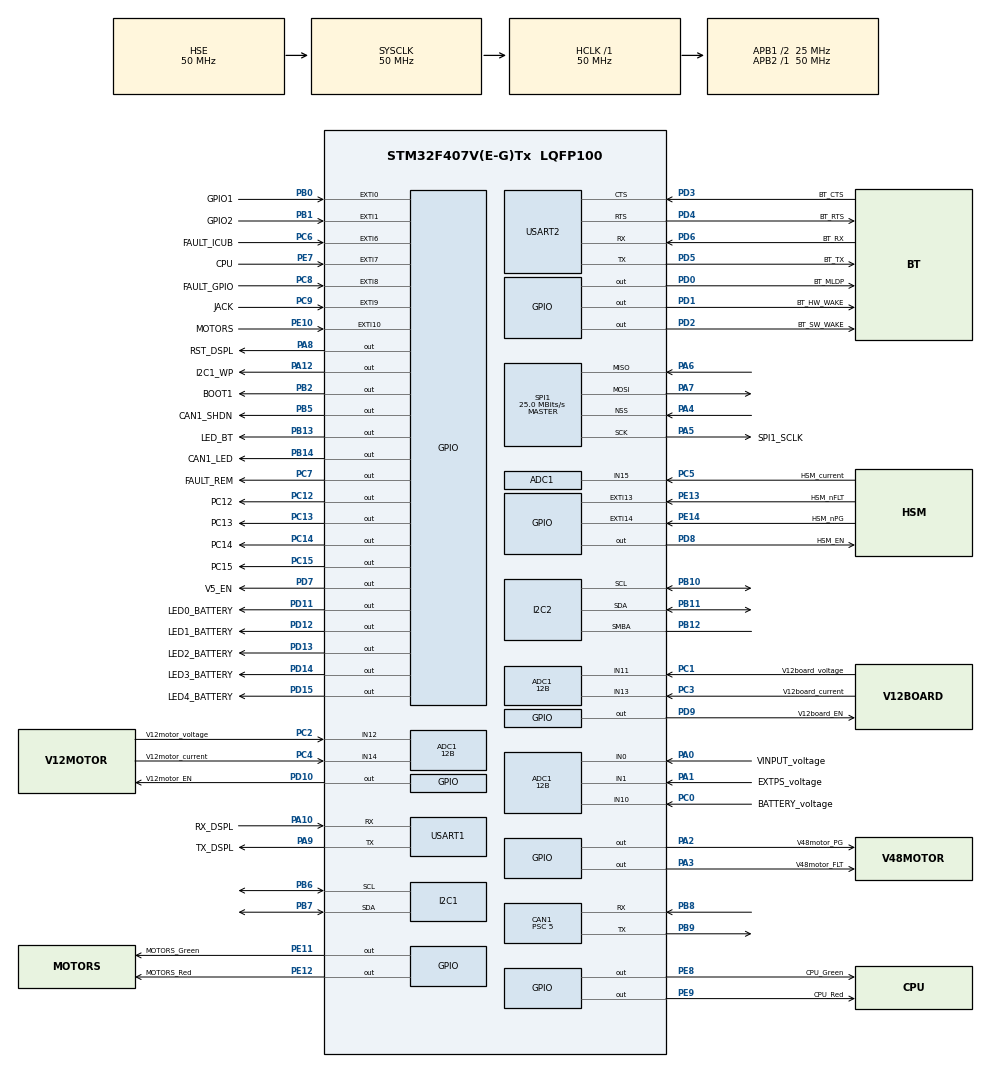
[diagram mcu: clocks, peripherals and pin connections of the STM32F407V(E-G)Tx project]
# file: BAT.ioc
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ADC1.Channel-10\#ChannelRegularConversion=ADC_CHANNEL_10
ADC1.Channel-11\#ChannelRegularConversion=ADC_CHANNEL_11
ADC1.Channel-12\#ChannelRegularConversion=ADC_CHANNEL_12
ADC1.Channel-13\#ChannelRegularConversion=ADC_CHANNEL_13
ADC1.Channel-14\#ChannelRegularConversion=ADC_CHANNEL_14
ADC1.Channel-15\#ChannelRegularConversion=ADC_CHANNEL_15
ADC1.Channel-16\#ChannelRegularConversion=ADC_CHANNEL_TEMPSENSOR
ADC1.Channel-5\#ChannelRegularConversion=ADC_CHANNEL_0
ADC1.Channel-9\#ChannelRegularConversion=ADC_CHANNEL_1
ADC1.ClockPrescaler=ADC_CLOCK_SYNC_PCLK_DIV8
ADC1.ContinuousConvMode=ENABLE
ADC1.DMAContinuousRequests=ENABLE
ADC1.DataAlign=ADC_DATAALIGN_RIGHT
ADC1.DiscontinuousConvMode=DISABLE
ADC1.EOCSelection=ADC_EOC_SEQ_CONV
ADC1.EnableAnalogWatchDog=false
ADC1.ExternalTrigConvEdge=ADC_EXTERNALTRIGCONVEDGE_NONE
ADC1.InjNumberOfConversion=0
ADC1.NbrOfConversion=9
ADC1.NbrOfConversionFlag=1
ADC1.Rank-10\#ChannelRegularConversion=3
ADC1.Rank-11\#ChannelRegularConversion=4
ADC1.Rank-12\#ChannelRegularConversion=5
ADC1.Rank-13\#ChannelRegularConversion=6
ADC1.Rank-14\#ChannelRegularConversion=7
ADC1.Rank-15\#ChannelRegularConversion=8
ADC1.Rank-16\#ChannelRegularConversion=9
ADC1.Rank-5\#ChannelRegularConversion=1
ADC1.Rank-9\#ChannelRegularConversion=2
ADC1.Resolution=ADC_RESOLUTION_12B
ADC1.SamplingTime-10\#ChannelRegularConversion=ADC_SAMPLETIME_15CYCLES
ADC1.SamplingTime-11\#ChannelRegularConversion=ADC_SAMPLETIME_15CYCLES
ADC1.SamplingTime-12\#ChannelRegularConversion=ADC_SAMPLETIME_15CYCLES
ADC1.SamplingTime-13\#ChannelRegularConversion=ADC_SAMPLETIME_15CYCLES
ADC1.SamplingTime-14\#ChannelRegularConversion=ADC_SAMPLETIME_15CYCLES
ADC1.SamplingTime-15\#ChannelRegularConversion=ADC_SAMPLETIME_15CYCLES
ADC1.SamplingTime-16\#ChannelRegularConversion=ADC_SAMPLETIME_15CYCLES
ADC1.SamplingTime-5\#ChannelRegularConversion=ADC_SAMPLETIME_15CYCLES
ADC1.SamplingTime-9\#ChannelRegularConversion=ADC_SAMPLETIME_15CYCLES
ADC1.ScanConvMode=ENABLE
ADC1.master=1
CAN1.ABOM=ENABLE
CAN1.AWUM=ENABLE
CAN1.BS1=CAN_BS1_2TQ
CAN1.BS2=CAN_BS2_2TQ
CAN1.CalculateTimeBit=600
CAN1.CalculateTimeQuantum=200.0
CAN1.Mode=CAN_MODE_LOOPBACK
CAN1.Prescaler=5
CAN1.TXFP=DISABLE
Dma.ADC1.3.Direction=DMA_PERIPH_TO_MEMORY
Dma.ADC1.3.FIFOMode=DMA_FIFOMODE_DISABLE
Dma.ADC1.3.Instance=DMA2_Stream0
Dma.ADC1.3.MemDataAlignment=DMA_MDATAALIGN_WORD
Dma.ADC1.3.MemInc=DMA_MINC_ENABLE
Dma.ADC1.3.Mode=DMA_CIRCULAR
Dma.ADC1.3.PeriphDataAlignment=DMA_PDATAALIGN_WORD
Dma.ADC1.3.PeriphInc=DMA_PINC_DISABLE
Dma.ADC1.3.Priority=DMA_PRIORITY_LOW
Dma.Request0=USART2_RX
Dma.Request1=USART2_TX
Dma.Request2=USART1_TX
Dma.Request3=ADC1
Dma.USART1_TX.2.Direction=DMA_MEMORY_TO_PERIPH
Dma.USART1_TX.2.FIFOMode=DMA_FIFOMODE_DISABLE
Dma.USART1_TX.2.Instance=DMA2_Stream7
Dma.USART1_TX.2.MemDataAlignment=DMA_MDATAALIGN_BYTE
Dma.USART1_TX.2.MemInc=DMA_MINC_ENABLE
Dma.USART1_TX.2.Mode=DMA_NORMAL
Dma.USART1_TX.2.PeriphDataAlignment=DMA_PDATAALIGN_BYTE
Dma.USART1_TX.2.PeriphInc=DMA_PINC_DISABLE
Dma.USART1_TX.2.Priority=DMA_PRIORITY_LOW
Dma.USART2_RX.0.Direction=DMA_PERIPH_TO_MEMORY
Dma.USART2_RX.0.FIFOMode=DMA_FIFOMODE_DISABLE
Dma.USART2_RX.0.Instance=DMA1_Stream5
Dma.USART2_RX.0.MemDataAlignment=DMA_MDATAALIGN_BYTE
Dma.USART2_RX.0.MemInc=DMA_MINC_ENABLE
Dma.USART2_RX.0.Mode=DMA_NORMAL
Dma.USART2_RX.0.PeriphDataAlignment=DMA_PDATAALIGN_BYTE
Dma.USART2_RX.0.PeriphInc=DMA_PINC_DISABLE
Dma.USART2_RX.0.Priority=DMA_PRIORITY_LOW
Dma.USART2_TX.1.Direction=DMA_MEMORY_TO_PERIPH
Dma.USART2_TX.1.FIFOMode=DMA_FIFOMODE_DISABLE
Dma.USART2_TX.1.Instance=DMA1_Stream6
Dma.USART2_TX.1.MemDataAlignment=DMA_MDATAALIGN_BYTE
Dma.USART2_TX.1.MemInc=DMA_MINC_ENABLE
Dma.USART2_TX.1.Mode=DMA_NORMAL
Dma.USART2_TX.1.PeriphDataAlignment=DMA_PDATAALIGN_BYTE
Dma.USART2_TX.1.PeriphInc=DMA_PINC_DISABLE
Dma.USART2_TX.1.Priority=DMA_PRIORITY_LOW
Mcu.Family=STM32F4
Mcu.Name=STM32F407V(E-G)Tx
Mcu.Package=LQFP100
NVIC.CAN1_RX0_IRQn=true\:0\:0\:false\:false\:true\:true
NVIC.CAN1_RX1_IRQn=true\:0\:0\:false\:false\:true\:true
NVIC.CAN1_SCE_IRQn=true\:0\:0\:false\:false\:true\:true
NVIC.CAN1_TX_IRQn=true\:0\:0\:false\:false\:true\:true
NVIC.DMA1_Stream5_IRQn=true\:0\:0\:false\:false\:true\:true
NVIC.DMA1_Stream6_IRQn=true\:0\:0\:false\:false\:true\:true
NVIC.DMA2_Stream0_IRQn=true\:0\:0\:false\:false\:true\:true
NVIC.DMA2_Stream7_IRQn=true\:0\:0\:false\:false\:true\:true
NVIC.EXTI0_IRQn=true\:0\:0\:false\:false\:true\:true
NVIC.EXTI15_10_IRQn=true\:0\:0\:false\:false\:true\:true
NVIC.EXTI1_IRQn=true\:0\:0\:false\:false\:true\:true
NVIC.EXTI9_5_IRQn=true\:0\:0\:false\:false\:true\:true
NVIC.PriorityGroup=NVIC_PRIORITYGROUP_4
NVIC.TIM1_TRG_COM_TIM11_IRQn=true\:0\:0\:false\:false\:true\:true
NVIC.TIM1_UP_TIM10_IRQn=true\:0\:0\:false\:false\:true\:true
NVIC.TIM2_IRQn=true\:0\:0\:false\:false\:true\:true
NVIC.TIM6_DAC_IRQn=true\:0\:0\:false\:false\:true\:true
NVIC.TIM7_IRQn=true\:0\:0\:false\:false\:true\:true
NVIC.TIM8_UP_TIM13_IRQn=true\:0\:0\:false\:false\:true\:true
NVIC.USART1_IRQn=true\:0\:0\:true\:false\:true\:true
NVIC.USART2_IRQn=true\:0\:0\:false\:false\:true\:true
PA0-WKUP.GPIO_Label=VINPUT_voltage
PA0-WKUP.GPIO_Mode=GPIO_MODE_ANALOG
PA0-WKUP.GPIO_PuPd=GPIO_NOPULL
PA0-WKUP.Signal=ADCx_IN0
PA1.GPIO_Label=EXTPS_voltage
PA1.GPIO_Mode=GPIO_MODE_ANALOG
PA1.GPIO_PuPd=GPIO_NOPULL
PA1.Signal=ADCx_IN1
PA10.GPIO_Label=RX_DSPL
PA10.GPIO_Mode=GPIO_MODE_AF_PP
PA10.GPIO_PuPd=GPIO_PULLUP
PA10.GPIO_Speed=GPIO_SPEED_FREQ_VERY_HIGH
PA10.Mode=Asynchronous
PA10.Signal=USART1_RX
PA12.GPIO_Label=I2C1_WP
PA12.GPIO_ModeDefaultOutputPP=GPIO_MODE_OUTPUT_PP
PA12.GPIO_PuPd=GPIO_NOPULL
PA12.GPIO_Speed=GPIO_SPEED_FREQ_LOW
PA12.Signal=GPIO_Output
PA13.Mode=Trace-Synchro(4bits)_JTAG
PA13.Signal=SYS_JTMS-SWDIO
PA14.Mode=Trace-Synchro(4bits)_JTAG
PA14.Signal=SYS_JTCK-SWCLK
PA15.Mode=Trace-Synchro(4bits)_JTAG
PA15.Signal=SYS_JTDI
PA2.GPIO_Label=V48motor_PG
PA2.GPIO_ModeDefaultOutputPP=GPIO_MODE_OUTPUT_PP
PA2.GPIO_PuPd=GPIO_NOPULL
PA2.GPIO_Speed=GPIO_SPEED_FREQ_LOW
PA2.Signal=GPIO_Output
PA3.GPIO_Label=V48motor_FLT
PA3.GPIO_ModeDefaultOutputPP=GPIO_MODE_OUTPUT_PP
PA3.GPIO_PuPd=GPIO_NOPULL
PA3.GPIO_Speed=GPIO_SPEED_FREQ_LOW
PA3.Signal=GPIO_Output
PA4.Mode=NSS_Signal_Hard_Input
PA4.Signal=SPI1_NSS
PA5.GPIO_Label=SPI1_SCLK
PA5.GPIO_Mode=GPIO_MODE_AF_PP
PA5.GPIO_PuPd=GPIO_NOPULL
PA5.GPIO_Speed=GPIO_SPEED_FREQ_VERY_HIGH
PA5.Mode=Full_Duplex_Master
PA5.Signal=SPI1_SCK
PA6.Mode=Full_Duplex_Master
PA6.Signal=SPI1_MISO
PA7.Mode=Full_Duplex_Master
PA7.Signal=SPI1_MOSI
PA8.GPIO_Label=RST_DSPL
PA8.GPIO_ModeDefaultOutputPP=GPIO_MODE_OUTPUT_PP
PA8.GPIO_PuPd=GPIO_NOPULL
PA8.GPIO_Speed=GPIO_SPEED_FREQ_LOW
PA8.Signal=GPIO_Output
PA9.GPIO_Label=TX_DSPL
PA9.GPIO_Mode=GPIO_MODE_AF_PP
PA9.GPIO_PuPd=GPIO_PULLUP
PA9.GPIO_Speed=GPIO_SPEED_FREQ_VERY_HIGH
PA9.Mode=Asynchronous
PA9.Signal=USART1_TX
PB0.GPIO_Label=GPIO1
PB0.GPIO_ModeDefaultEXTI=GPIO_MODE_IT_FALLING
PB0.GPIO_PuPd=GPIO_PULLUP
PB0.Signal=GPXTI0
PB1.GPIO_Label=GPIO2
PB1.GPIO_ModeDefaultEXTI=GPIO_MODE_IT_FALLING
PB1.GPIO_PuPd=GPIO_PULLUP
PB1.Signal=GPXTI1
PB10.Mode=SMBus-Alert-mode
PB10.Signal=I2C2_SCL
PB11.Mode=SMBus-Alert-mode
PB11.Signal=I2C2_SDA
PB12.Mode=SMBus-Alert-mode
PB12.Signal=I2C2_SMBA
PB13.GPIO_Label=LED_BT
PB13.GPIO_ModeDefaultOutputPP=GPIO_MODE_OUTPUT_PP
PB13.GPIO_PuPd=GPIO_NOPULL
PB13.GPIO_Speed=GPIO_SPEED_FREQ_LOW
PB13.Signal=GPIO_Output
PB14.GPIO_Label=CAN1_LED
PB14.GPIO_ModeDefaultOutputPP=GPIO_MODE_OUTPUT_PP
PB14.GPIO_PuPd=GPIO_NOPULL
PB14.GPIO_Speed=GPIO_SPEED_FREQ_LOW
PB14.Signal=GPIO_Output
PB2.GPIO_Label=BOOT1
PB2.GPIO_ModeDefaultOutputPP=GPIO_MODE_OUTPUT_PP
PB2.GPIO_PuPd=GPIO_NOPULL
PB2.GPIO_Speed=GPIO_SPEED_FREQ_LOW
PB2.Signal=GPIO_Output
PB3.Mode=Trace-Synchro(4bits)_JTAG
PB3.Signal=SYS_JTDO-SWO
PB5.GPIO_Label=CAN1_SHDN
PB5.GPIO_ModeDefaultOutputPP=GPIO_MODE_OUTPUT_PP
PB5.GPIO_PuPd=GPIO_NOPULL
PB5.GPIO_Speed=GPIO_SPEED_FREQ_LOW
PB5.Signal=GPIO_Output
PB6.Mode=I2C
PB6.Signal=I2C1_SCL
PB7.Mode=I2C
PB7.Signal=I2C1_SDA
PB8.Mode=Master
PB8.Signal=CAN1_RX
PB9.Mode=Master
PB9.Signal=CAN1_TX
PC0.GPIO_Label=BATTERY_voltage
PC0.GPIO_Mode=GPIO_MODE_ANALOG
PC0.GPIO_PuPd=GPIO_NOPULL
PC0.Signal=ADCx_IN10
PC1.GPIO_Label=V12board_voltage
PC1.GPIO_Mode=GPIO_MODE_ANALOG
PC1.GPIO_PuPd=GPIO_NOPULL
PC1.Signal=ADCx_IN11
PC12.GPIO_Label=PC12
PC12.GPIO_ModeDefaultOutputPP=GPIO_MODE_OUTPUT_PP
PC12.GPIO_PuPd=GPIO_NOPULL
PC12.GPIO_Speed=GPIO_SPEED_FREQ_LOW
PC12.Signal=GPIO_Output
PC13-ANTI_TAMP.GPIO_Label=PC13
PC13-ANTI_TAMP.GPIO_ModeDefaultOutputPP=GPIO_MODE_OUTPUT_PP
PC13-ANTI_TAMP.GPIO_PuPd=GPIO_NOPULL
PC13-ANTI_TAMP.GPIO_Speed=GPIO_SPEED_FREQ_LOW
PC13-ANTI_TAMP.Signal=GPIO_Output
PC14-OSC32_IN.GPIO_Label=PC14
PC14-OSC32_IN.GPIO_ModeDefaultOutputPP=GPIO_MODE_OUTPUT_PP
PC14-OSC32_IN.GPIO_PuPd=GPIO_NOPULL
PC14-OSC32_IN.GPIO_Speed=GPIO_SPEED_FREQ_LOW
PC14-OSC32_IN.Signal=GPIO_Output
PC15-OSC32_OUT.GPIO_Label=PC15
PC15-OSC32_OUT.GPIO_ModeDefaultOutputPP=GPIO_MODE_OUTPUT_PP
PC15-OSC32_OUT.GPIO_PuPd=GPIO_NOPULL
PC15-OSC32_OUT.GPIO_Speed=GPIO_SPEED_FREQ_LOW
PC15-OSC32_OUT.Signal=GPIO_Output
PC2.GPIO_Label=V12motor_voltage
PC2.GPIO_Mode=GPIO_MODE_ANALOG
PC2.GPIO_PuPd=GPIO_NOPULL
PC2.Signal=ADCx_IN12
PC3.GPIO_Label=V12board_current
PC3.GPIO_Mode=GPIO_MODE_ANALOG
PC3.GPIO_PuPd=GPIO_NOPULL
PC3.Signal=ADCx_IN13
PC4.GPIO_Label=V12motor_current
PC4.GPIO_Mode=GPIO_MODE_ANALOG
PC4.GPIO_PuPd=GPIO_NOPULL
PC4.Signal=ADCx_IN14
PC5.GPIO_Label=HSM_current
PC5.GPIO_Mode=GPIO_MODE_ANALOG
PC5.GPIO_PuPd=GPIO_NOPULL
PC5.Signal=ADCx_IN15
PC6.GPIO_Label=FAULT_ICUB
PC6.GPIO_ModeDefaultEXTI=GPIO_MODE_IT_FALLING
PC6.GPIO_PuPd=GPIO_PULLUP
PC6.Signal=GPXTI6
PC7.GPIO_Label=FAULT_REM
PC7.GPIO_ModeDefaultOutputPP=GPIO_MODE_OUTPUT_PP
PC7.GPIO_PuPd=GPIO_PULLDOWN
PC7.GPIO_Speed=GPIO_SPEED_FREQ_LOW
PC7.Signal=GPIO_Output
PC8.GPIO_Label=FAULT_GPIO
PC8.GPIO_ModeDefaultEXTI=GPIO_MODE_IT_FALLING
PC8.GPIO_PuPd=GPIO_PULLUP
PC8.Signal=GPXTI8
PC9.GPIO_Label=JACK
PC9.GPIO_ModeDefaultEXTI=GPIO_MODE_IT_FALLING
PC9.GPIO_PuPd=GPIO_PULLUP
PC9.Signal=GPXTI9
PD0.GPIO_Label=BT_MLDP
PD0.GPIO_ModeDefaultOutputPP=GPIO_MODE_OUTPUT_PP
PD0.GPIO_PuPd=GPIO_NOPULL
PD0.GPIO_Speed=GPIO_SPEED_FREQ_LOW
PD0.Signal=GPIO_Output
PD1.GPIO_Label=BT_HW_WAKE
PD1.GPIO_ModeDefaultOutputPP=GPIO_MODE_OUTPUT_PP
PD1.GPIO_PuPd=GPIO_NOPULL
PD1.GPIO_Speed=GPIO_SPEED_FREQ_LOW
PD1.Signal=GPIO_Output
PD10.GPIO_Label=V12motor_EN
PD10.GPIO_ModeDefaultOutputPP=GPIO_MODE_OUTPUT_PP
PD10.GPIO_PuPd=GPIO_NOPULL
PD10.GPIO_Speed=GPIO_SPEED_FREQ_LOW
PD10.Signal=GPIO_Output
PD11.GPIO_Label=LED0_BATTERY
PD11.GPIO_ModeDefaultOutputPP=GPIO_MODE_OUTPUT_PP
PD11.GPIO_PuPd=GPIO_NOPULL
PD11.GPIO_Speed=GPIO_SPEED_FREQ_LOW
PD11.Signal=GPIO_Output
PD12.GPIO_Label=LED1_BATTERY
PD12.GPIO_ModeDefaultOutputPP=GPIO_MODE_OUTPUT_PP
PD12.GPIO_PuPd=GPIO_NOPULL
PD12.GPIO_Speed=GPIO_SPEED_FREQ_LOW
PD12.Signal=GPIO_Output
PD13.GPIO_Label=LED2_BATTERY
PD13.GPIO_ModeDefaultOutputPP=GPIO_MODE_OUTPUT_PP
PD13.GPIO_PuPd=GPIO_NOPULL
PD13.GPIO_Speed=GPIO_SPEED_FREQ_LOW
PD13.Signal=GPIO_Output
PD14.GPIO_Label=LED3_BATTERY
PD14.GPIO_ModeDefaultOutputPP=GPIO_MODE_OUTPUT_PP
PD14.GPIO_PuPd=GPIO_NOPULL
PD14.GPIO_Speed=GPIO_SPEED_FREQ_LOW
PD14.Signal=GPIO_Output
PD15.GPIO_Label=LED4_BATTERY
PD15.GPIO_ModeDefaultOutputPP=GPIO_MODE_OUTPUT_PP
PD15.GPIO_PuPd=GPIO_NOPULL
PD15.GPIO_Speed=GPIO_SPEED_FREQ_LOW
PD15.Signal=GPIO_Output
PD2.GPIO_Label=BT_SW_WAKE
PD2.GPIO_ModeDefaultOutputPP=GPIO_MODE_OUTPUT_PP
PD2.GPIO_PuPd=GPIO_NOPULL
PD2.GPIO_Speed=GPIO_SPEED_FREQ_LOW
PD2.Signal=GPIO_Output
PD3.GPIO_Label=BT_CTS
PD3.GPIO_Mode=GPIO_MODE_AF_PP
PD3.GPIO_PuPd=GPIO_NOPULL
PD3.GPIO_Speed=GPIO_SPEED_FREQ_VERY_HIGH
PD3.Mode=CTS_RTS
PD3.Signal=USART2_CTS
PD4.GPIO_Label=BT_RTS
PD4.GPIO_Mode=GPIO_MODE_AF_PP
PD4.GPIO_PuPd=GPIO_NOPULL
PD4.GPIO_Speed=GPIO_SPEED_FREQ_VERY_HIGH
PD4.Mode=CTS_RTS
PD4.Signal=USART2_RTS
PD5.GPIO_Label=BT_TX
PD5.GPIO_Mode=GPIO_MODE_AF_PP
PD5.GPIO_PuPd=GPIO_PULLUP
PD5.GPIO_Speed=GPIO_SPEED_FREQ_VERY_HIGH
PD5.Mode=Asynchronous
PD5.Signal=USART2_TX
PD6.GPIO_Label=BT_RX
PD6.GPIO_Mode=GPIO_MODE_AF_PP
PD6.GPIO_PuPd=GPIO_PULLUP
PD6.GPIO_Speed=GPIO_SPEED_FREQ_VERY_HIGH
PD6.Mode=Asynchronous
PD6.Signal=USART2_RX
PD7.GPIO_Label=V5_EN
PD7.GPIO_ModeDefaultOutputPP=GPIO_MODE_OUTPUT_PP
PD7.GPIO_PuPd=GPIO_NOPULL
PD7.GPIO_Speed=GPIO_SPEED_FREQ_LOW
PD7.Signal=GPIO_Output
PD8.GPIO_Label=HSM_EN
PD8.GPIO_ModeDefaultOutputPP=GPIO_MODE_OUTPUT_PP
PD8.GPIO_PuPd=GPIO_NOPULL
PD8.GPIO_Speed=GPIO_SPEED_FREQ_LOW
PD8.Signal=GPIO_Output
PD9.GPIO_Label=V12board_EN
PD9.GPIO_ModeDefaultOutputPP=GPIO_MODE_OUTPUT_PP
PD9.GPIO_PuPd=GPIO_NOPULL
PD9.GPIO_Speed=GPIO_SPEED_FREQ_LOW
PD9.Signal=GPIO_Output
PE10.GPIO_Label=MOTORS
PE10.GPIO_ModeDefaultEXTI=GPIO_MODE_IT_FALLING
PE10.GPIO_PuPd=GPIO_PULLUP
PE10.Signal=GPXTI10
PE11.GPIO_Label=MOTORS_Green
PE11.GPIO_ModeDefaultOutputPP=GPIO_MODE_OUTPUT_PP
PE11.GPIO_PuPd=GPIO_NOPULL
PE11.GPIO_Speed=GPIO_SPEED_FREQ_LOW
PE11.Signal=GPIO_Output
PE12.GPIO_Label=MOTORS_Red
PE12.GPIO_ModeDefaultOutputPP=GPIO_MODE_OUTPUT_PP
PE12.GPIO_PuPd=GPIO_NOPULL
PE12.GPIO_Speed=GPIO_SPEED_FREQ_LOW
PE12.Signal=GPIO_Output
PE13.GPIO_Label=HSM_nFLT
PE13.GPIO_ModeDefaultEXTI=GPIO_MODE_IT_RISING_FALLING
PE13.GPIO_PuPd=GPIO_PULLUP
PE13.Signal=GPXTI13
PE14.GPIO_Label=HSM_nPG
PE14.GPIO_ModeDefaultEXTI=GPIO_MODE_IT_RISING_FALLING
PE14.GPIO_PuPd=GPIO_PULLUP
PE14.Signal=GPXTI14
PE2.Mode=Trace-Synchro(4bits)_JTAG
PE2.Signal=SYS_TRACECLK
PE3.Mode=Trace-Synchro(4bits)_JTAG
PE3.Signal=SYS_TRACED0
PE4.Mode=Trace-Synchro(4bits)_JTAG
PE4.Signal=SYS_TRACED1
PE5.Mode=Trace-Synchro(4bits)_JTAG
PE5.Signal=SYS_TRACED2
PE6.Mode=Trace-Synchro(4bits)_JTAG
PE6.Signal=SYS_TRACED3
PE7.GPIO_Label=CPU
PE7.GPIO_ModeDefaultEXTI=GPIO_MODE_IT_FALLING
PE7.GPIO_PuPd=GPIO_PULLUP
PE7.Signal=GPXTI7
PE8.GPIO_Label=CPU_Green
PE8.GPIO_ModeDefaultOutputPP=GPIO_MODE_OUTPUT_PP
PE8.GPIO_PuPd=GPIO_NOPULL
PE8.GPIO_Speed=GPIO_SPEED_FREQ_LOW
PE8.Signal=GPIO_Output
PE9.GPIO_Label=CPU_Red
PE9.GPIO_ModeDefaultOutputPP=GPIO_MODE_OUTPUT_PP
PE9.GPIO_PuPd=GPIO_NOPULL
PE9.GPIO_Speed=GPIO_SPEED_FREQ_LOW
PE9.Signal=GPIO_Output
PH0-OSC_IN.Mode=HSE-External-Clock-Source
PH0-OSC_IN.Signal=RCC_OSC_IN
PH1-OSC_OUT.Mode=HSE-External-Clock-Source
PH1-OSC_OUT.Signal=RCC_OSC_OUT
ProjectManager.HeapSize=0x200
ProjectManager.StackSize=0x400
ProjectManager.TargetToolchain=MDK-ARM V5
RCC.48MHZClocksFreq_Value=150000000
RCC.AHBFreq_Value=50000000
RCC.APB1CLKDivider=RCC_HCLK_DIV2
RCC.APB1Freq_Value=25000000
RCC.APB1TimFreq_Value=50000000
RCC.APB2Freq_Value=50000000
RCC.APB2TimFreq_Value=50000000
RCC.CortexFreq_Value=50000000
RCC.HCLKFreq_Value=50000000
RCC.HSE_VALUE=50000000
RCC.HSI_VALUE=16000000
RCC.LSE_VALUE=32768
RCC.PLLSourceVirtual=RCC_PLLSOURCE_HSE
RCC.SYSCLKFreq_VALUE=50000000
RCC.SYSCLKSource=RCC_SYSCLKSOURCE_HSE
RCC.VCOOutputFreq_Value=600000000
SH.ADCx_IN0.0=ADC1_IN0,IN0
SH.ADCx_IN1.0=ADC1_IN1,IN1
SH.ADCx_IN10.0=ADC1_IN10,IN10
SH.ADCx_IN11.0=ADC1_IN11,IN11
SH.ADCx_IN12.0=ADC1_IN12,IN12
SH.ADCx_IN13.0=ADC1_IN13,IN13
SH.ADCx_IN14.0=ADC1_IN14,IN14
SH.ADCx_IN15.0=ADC1_IN15,IN15
SPI1.CalculateBaudRate=25.0 MBits/s
SPI1.Direction=SPI_DIRECTION_2LINES
SPI1.Mode=SPI_MODE_MASTER
SPI1.VirtualNSS=VM_NSSHARD
SPI1.VirtualType=VM_MASTER
TIM1.Period=5000
TIM1.Prescaler=100
TIM10.Period=5000
TIM10.Prescaler=100
TIM11.Period=5000
TIM11.Prescaler=1000
TIM13.Period=5000
TIM13.Prescaler=10000
TIM2.Period=5000
TIM2.Prescaler=100
TIM6.Period=5000
TIM6.Prescaler=0
TIM6.TIM_MasterOutputTrigger=TIM_TRGO_RESET
TIM7.Period=5000
TIM7.Prescaler=10
USART1.VirtualMode=VM_ASYNC
USART2.VirtualMode=VM_ASYNC
VP_ADC1_TempSens_Input.Mode=IN-TempSens
VP_TIM10_VS_ClockSourceINT.Mode=Enable_Timer
VP_TIM11_VS_ClockSourceINT.Mode=Enable_Timer
VP_TIM13_VS_ClockSourceINT.Mode=Enable_Timer
VP_TIM1_VS_ClockSourceINT.Mode=Internal
VP_TIM2_VS_ClockSourceINT.Mode=Internal
VP_TIM6_VS_ClockSourceINT.Mode=Enable_Timer
VP_TIM7_VS_ClockSourceINT.Mode=Enable_Timer
board=BAT

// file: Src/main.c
/**
  ******************************************************************************
  * File Name          : main.c
  * Description        : Main program body
  ******************************************************************************
  *
  * COPYRIGHT(c) 2018 STMicroelectronics
  *
  * Redistribution and use in source and binary forms, with or without modification,
  * are permitted provided that the following conditions are met:
  *   1. Redistributions of source code must retain the above copyright notice,
  *      this list of conditions and the following disclaimer.
  *   2. Redistributions in binary form must reproduce the above copyright notice,
  *      this list of conditions and the following disclaimer in the documentation
  *      and/or other materials provided with the distribution.
  *   3. Neither the name of STMicroelectronics nor the names of its contributors
  *      may be used to endorse or promote products derived from this software
  *      without specific prior written permission.
  *
  * THIS SOFTWARE IS PROVIDED BY THE COPYRIGHT HOLDERS AND CONTRIBUTORS "AS IS"
  * AND ANY EXPRESS OR IMPLIED WARRANTIES, INCLUDING, BUT NOT LIMITED TO, THE
  * IMPLIED WARRANTIES OF MERCHANTABILITY AND FITNESS FOR A PARTICULAR PURPOSE ARE
  * DISCLAIMED. IN NO EVENT SHALL THE COPYRIGHT HOLDER OR CONTRIBUTORS BE LIABLE
  * FOR ANY DIRECT, INDIRECT, INCIDENTAL, SPECIAL, EXEMPLARY, OR CONSEQUENTIAL
  * DAMAGES (INCLUDING, BUT NOT LIMITED TO, PROCUREMENT OF SUBSTITUTE GOODS OR
  * SERVICES; LOSS OF USE, DATA, OR PROFITS; OR BUSINESS INTERRUPTION) HOWEVER
  * CAUSED AND ON ANY THEORY OF LIABILITY, WHETHER IN CONTRACT, STRICT LIABILITY,
  * OR TORT (INCLUDING NEGLIGENCE OR OTHERWISE) ARISING IN ANY WAY OUT OF THE USE
  * OF THIS SOFTWARE, EVEN IF ADVISED OF THE POSSIBILITY OF SUCH DAMAGE.
  *
  ******************************************************************************
  */
#include "stm32f4xx_hal.h"
#include "adc.h"
#include "can.h"
#include "dma.h"
#include "i2c.h"
#include "spi.h"
#include "tim.h"
#include "usart.h"
#include "gpio.h"

/* USER CODE BEGIN Includes */
#include "define.h"

/* USER CODE END Includes */

/* USER CODE BEGIN PV */

// ----------------------------------------------------------------------------
// Firmware Version
// ----------------------------------------------------------------------------
char Firmware_vers = 1;
char Revision_vers = 1;
char Build_number  = 0;

/* Private variables ---------------------------------------------------------*/
typedef struct
{
  uint32_t V_VINPUT;
  uint32_t V_EXTPS;
  uint32_t V_BATTERY;
  uint32_t V_V12board;
  uint32_t V_V12motor;
  int32_t I_V12board;
  int32_t I_V12motor;
  int32_t I_HSM;
  int32_t Temp_sensor;
}adc_measure_t;

adc_measure_t adc_measure = {0};  // initialize all adc values to 0
adc_measure_t mean = {0};         // initialize all average values to 0
uint32_t adc_values[9];           // contains all ADC channels conversion

#define nr_adc_sample (uint16_t) 400 // number of samples for the average measure
uint16_t adc_sample = 0;

typedef struct
{
  uint32_t V_VINPUT[nr_adc_sample];
  uint32_t V_EXTPS[nr_adc_sample];
  uint32_t V_BATTERY[nr_adc_sample];
  uint32_t V_V12board[nr_adc_sample];
  uint32_t V_V12motor[nr_adc_sample];
  int32_t I_V12board[nr_adc_sample];
  int32_t I_V12motor[nr_adc_sample];
  int32_t I_HSM[nr_adc_sample];
}fifo;

fifo adc_samples = {0};

#ifdef BAT_R1
uint32_t VTH[7]={23000, 24000, 25000, 26000, 27000, 28000, 29000};   // threshold in mV R1 Battery
uint16_t Battery_high=4200*7;   // 7s5p battery
uint16_t Battery_low=3300*7;    // 7s5p battery
#endif

#ifdef BAT_iCub3
uint32_t VTH[7]={32000, 34000, 36000, 38000, 40000, 42000, 44000};   // threshold in mV iCub 2.5 Battery
uint16_t Battery_high=4200*10;   // 10s3p battery
uint16_t Battery_low=3300*10;    // 10s3p battery
#endif

uint32_t vtol=100;  // voltage tolerance for hysteresis
uint32_t vhyst=0;    // voltage hysteresis
uint16_t Battery_charge;

uint8_t PB1_debounce    = 0;
uint8_t PB1_restart     = 0;
uint8_t PB1_status      = 1;
uint8_t PB1_counter_debounce;

uint8_t PB2_debounce    = 0;
uint8_t PB2_restart     = 0;
uint8_t PB2_status      = 1;
uint8_t PB2_counter_debounce;

uint8_t int_fault         = 0;
uint8_t filter_fault_gpio = 0;
uint8_t fault_button      = 0;

uint8_t timer_debounce  = 10;     // 10x (10ms timer) = 100ms
uint8_t timer_restart   = 100;    // 100x (10ms timer) = 1s
uint16_t timer_delay_dcdc  = 0;           // delay between switching on V12board and then V12motor
uint16_t timer_delay_board = 0;
uint16_t timer_delay_motor = 0;
uint16_t timer_delay_board_max = 500;
uint16_t timer_delay_motor_max = 10000;
uint16_t timer_delay_dcdc_max  = 10000;   // delay between switching on regulator

uint32_t blink_ds=100;
uint8_t toggle_1s = 0;
uint8_t toggle_100ms = 0;

uint16_t I_V12board_MAX      = 9000;     // threshold in mA
uint16_t I_V12motor_MAX      = 6500;     // threshold in mA
uint16_t I_HSM_MAX           = 20000;
uint16_t timer_fault_board   = 0;
uint16_t timer_fault_motors  = 0;
uint16_t timer_fault_HSM     = 0;
uint16_t timer_mosfet_broken = 0;
uint16_t timer_rearmHSM      = 0;
uint16_t rearmHSM_timevalue  = 20000;    // (value in second) = rearmHSM_timevalue * (loop in ms where is "timer_rearmHSM++")

uint8_t V12board      = 0;		// DCDC board control
uint8_t V12board_F    = 0;		// fault
uint8_t V12motor      = 0;		// DCDC motor control
uint8_t V12motor_F    = 0;		// fault
uint8_t HSM_broken    = 0;		// HSM transistors broken
uint8_t HSM           = 0;		// HSM control
uint8_t DCrestart     = 0;

uint8_t V12board_bdc  = 1;    // +++++++++++++++++++++++++++++++++++++++++++++ da cambiare logica ++++++++++++++++++
uint8_t V12motor_bdc  = 1;    // +++++++++++++++++++++++++++++++++++++++++++++ da cambiare logica ++++++++++++++++++

uint8_t state_fsm        = START;
uint8_t state_fsm_boards = START;
uint8_t state_fsm_motors = START;
uint8_t state_fsm_prev;
uint8_t state_fsm_boards_prev;
uint8_t state_fsm_motors_prev;
uint8_t timerFSM      = 0;
uint8_t timerFSM_boards = 0;
uint8_t timerFSM_motors = 0;

uint8_t DCDC_status_A = 0;
uint8_t DCDC_status_B = 0;
uint8_t DCDC_ctrl     = 0;
uint8_t HSM_PG        = 0;
uint8_t HSM_F         = 0;

__IO ITStatus UartReady = RESET;
uint16_t timeout    = 0;
uint16_t time_delay = 500;

uint8_t can_message = 0;

uint8_t RN4020_Reset[] = "SF,1,2\r\n";
uint8_t RN4020_Reboot[] = "R,1\r\n";
uint8_t RN4020_Setting_A[] = "SS,C0000000\r\n";		// Support Device Info and Battery as server
//uint8_t RN4020_Setting_A[] = "SS,30000000\r\n";		// Support Heart Rate and Health Thermometer services as server. (Page 93 datasheet)
uint8_t RN4020_Setting_B[] = "SR,00000000\r\n";
//uint8_t RN4020_Setting_B[] = "SR,92000000\r\n";		// Set device as central, support MLDP and enable, UART flow control
//uint8_t RN4020_Setting_B[] = "SR,32000000\r\n";		// Set device as peripheral with automatic advertisement, and support for MLDP and flow control features
uint8_t RN4020_Setting_C[] = "SN,bat_board\r\n";
uint8_t RN4020_Advertise[] = "A\r\n";
uint8_t aRxBuffer[50]={0};
char *RN_start = "CMD\r\n";
char *RN_reboot = "Reboot\r\n";
char *RN_ok = "AOK\r\n";

uint16_t uOLED_Parameters[14] = {0};
uint16_t Display_qualifier = 0x01;

/* USER CODE END PV */

void SystemClock_Config(void);

/* USER CODE BEGIN PFP */
/* Private function prototypes -----------------------------------------------*/
static void Error_Handler(void);
static void CAN_Config(void);
void CANBUS(void);
void Display_uOLED_128_G2(void);
void Bluetooth(void);
void WaitUartResponse(uint8_t* response);
static uint16_t Buffercmp(uint8_t* pBuffer1, uint8_t* pBuffer2, uint16_t BufferLength);
void displayCharge(void);
void calcMean(void);
void lightupLed(uint16_t lightup);
void checkHSM(void);
void dcdc_management(void);
void FAULT_CHECK(void);

/* USER CODE END PFP */

int main(void)
{

  /* MCU Configuration----------------------------------------------------------*/

  /* Reset of all peripherals, Initializes the Flash interface and the Systick. */
  HAL_Init();

  /* Configure the system clock */
  SystemClock_Config();

  /* Initialize all configured peripherals */
  MX_GPIO_Init();
  MX_DMA_Init();
  MX_ADC1_Init();
  MX_CAN1_Init();
  MX_I2C1_Init();
  MX_I2C2_Init();
  MX_SPI1_Init();
  MX_TIM1_Init();
  MX_TIM10_Init();
  MX_TIM11_Init();
  MX_TIM13_Init();
  MX_TIM2_Init();
  MX_TIM6_Init();
  MX_TIM7_Init();
  MX_USART1_UART_Init();
  MX_USART2_UART_Init();
  SystemClock_Config();

  /* USER CODE BEGIN 2 */
//  HAL_TIM_Base_Start_IT(&htim6);    // 100us
  HAL_TIM_Base_Start_IT(&htim7);    // 1ms
  HAL_TIM_Base_Start_IT(&htim10);   // 10ms
  HAL_TIM_Base_Start_IT(&htim11);   // 100ms
  HAL_TIM_Base_Start_IT(&htim13);   // 1s
  HAL_TIM_IRQHandler(&htim1);
  HAL_TIM_IRQHandler(&htim2);
//  HAL_TIM_IRQHandler(&htim6);
  HAL_TIM_IRQHandler(&htim7);
  HAL_TIM_IRQHandler(&htim10);
  HAL_TIM_IRQHandler(&htim11);
  HAL_TIM_IRQHandler(&htim13);

  //HAL_ADC_Start(&hadc1);
  HAL_ADC_Start_DMA(&hadc1, (uint32_t*)adc_values, 9);
  /* USER CODE END 2 */

  /* Infinite loop */
  /* USER CODE BEGIN WHILE */
  //Bluetooth();
  CAN_Config();
  V5_EN_ON;
  RST_DSPL_ON;
  FAULT_REM_ON;
  LED_BT_OFF;

  uOLED_Parameters[0]  = ((sizeof(uOLED_Parameters))<<8) +  Display_qualifier;
  uOLED_Parameters[1] = (Firmware_vers<<8) + (Revision_vers<<4) + (Build_number);

  while (1)
  {
  /* USER CODE END WHILE */

  }

}

/** System Clock Configuration
*/
void SystemClock_Config(void)
{

  RCC_OscInitTypeDef RCC_OscInitStruct;
  RCC_ClkInitTypeDef RCC_ClkInitStruct;

  __HAL_RCC_PWR_CLK_ENABLE();

  __HAL_PWR_VOLTAGESCALING_CONFIG(PWR_REGULATOR_VOLTAGE_SCALE1);

  RCC_OscInitStruct.OscillatorType = RCC_OSCILLATORTYPE_HSE;
  RCC_OscInitStruct.HSEState = RCC_HSE_BYPASS;
  RCC_OscInitStruct.PLL.PLLState = RCC_PLL_NONE;
  HAL_RCC_OscConfig(&RCC_OscInitStruct);

  RCC_ClkInitStruct.ClockType = RCC_CLOCKTYPE_HCLK|RCC_CLOCKTYPE_SYSCLK
                              |RCC_CLOCKTYPE_PCLK1|RCC_CLOCKTYPE_PCLK2;
  RCC_ClkInitStruct.SYSCLKSource = RCC_SYSCLKSOURCE_HSE;
  RCC_ClkInitStruct.AHBCLKDivider = RCC_SYSCLK_DIV1;
  RCC_ClkInitStruct.APB1CLKDivider = RCC_HCLK_DIV2;
  RCC_ClkInitStruct.APB2CLKDivider = RCC_HCLK_DIV1;
  HAL_RCC_ClockConfig(&RCC_ClkInitStruct, FLASH_LATENCY_1);

  HAL_SYSTICK_Config(HAL_RCC_GetHCLKFreq()/1000);

  HAL_SYSTICK_CLKSourceConfig(SYSTICK_CLKSOURCE_HCLK);

  /* SysTick_IRQn interrupt configuration */
  HAL_NVIC_SetPriority(SysTick_IRQn, 0, 0);
}

/* USER CODE BEGIN 4 */

// -----------------------------------------------------------------------------------------------------------------------------
// Finite state machine - DCDC power management - Target BAT_iCub3
// -----------------------------------------------------------------------------------------------------------------------------
#ifdef BAT_iCub3
void dcdc_management(void){

  // ----- EVENTS -------------------------------------------------- //
  if(!V12board_F){
    if(PB1_debounce){
      PB1_debounce=0;
      if(V12board)    {state_fsm_boards = OFF_BOARD;}
      else            {state_fsm_boards = ON_BOARD;}
    }
  }
  else{
    if(PB1_restart){
      state_fsm_boards = ON_BOARD;
      V12board_F=0;
      PB1_restart=0;
    }
    else{
      state_fsm_boards = FAULT_BOARD;
    }
  }

  if(!V12motor_F && !HSM_F){
    if(PB2_debounce){
      PB2_debounce=0;
      if(V12motor)    {state_fsm_motors = OFF_MOTORS;}
      else            {state_fsm_motors = ON_MOTORS;}
    }
  }
  else{
    if(PB2_restart){
      state_fsm_motors = ON_MOTORS;
      V12motor_F=0;
      PB2_restart=0;
    }
    else{
      state_fsm_motors = FAULT_MOTORS;
    }
  }

  // ----- FINITE STATE MACHINE ------------------------------------ //

	switch(state_fsm_boards){

		case START:
		{
      timerFSM_boards++;
			state_fsm_boards_prev = START;

			if(timerFSM_boards >= 10){
				state_fsm_boards = READY;
			}
    }
		break;

		case READY:
		{
      timerFSM_boards = 0;
			PB1_LED_RED;
		}
    break;

		case OFF_BOARD:
		{
      EN_V12board_OFF;
      V12board=0;
			PB1_LED_RED;
    }
    break;

		case ON_BOARD:
    {
      if(timer_delay_board < timer_delay_board_max){
        timer_delay_board++;
      }
      else{
        EN_V12board_ON;
        V12board=1;
        timer_delay_board=0;
      }
			if(V12board==0){
        if(toggle_100ms)  {PB1_LED_GREEN;}
        else              {PB1_LED_OFF;}
			}
      else                {PB1_LED_GREEN;}
		}
    break;

   	case FAULT_BOARD:
		{
      EN_V12board_OFF;
      V12board=0;
			if(toggle_100ms)  {PB1_LED_RED;}
			else              {PB1_LED_OFF;}
		}
    break;

    default:
		{

    }
		break;
	}

  switch(state_fsm_motors){

		case START:
		{
      timerFSM_motors++;
			state_fsm_motors_prev = START;

			if(timerFSM_motors >= 10){
				state_fsm_motors = READY;
			}
    }
		break;

		case READY:
		{
      timerFSM_motors = 0;
			PB2_LED_RED;
		}
    break;

		case OFF_MOTORS:
		{
      EN_V12motor_OFF;
      HSM_EN_OFF;
      V12motor=0;
      HSM=0;
			PB2_LED_RED;
    }
    break;

		case ON_MOTORS:
    {
      if(timer_delay_motor < timer_delay_motor_max){
        timer_delay_motor++;
      }
      else{
        EN_V12motor_ON;
        HSM_EN_ON;
        V12motor=1;
        HSM=1;
        timer_delay_motor=0;
      }
			if(HSM_PG==0){
        if(toggle_100ms)  {PB2_LED_GREEN;}
        else              {PB2_LED_OFF;}
			}
      else                {PB2_LED_GREEN;}
		}
    break;

		case FAULT_MOTORS:
		{
      EN_V12motor_OFF;
      HSM_EN_OFF;
      V12motor=0;
			HSM=0;
      if(toggle_100ms)  {PB2_LED_RED;}
			else              {PB2_LED_OFF;}
		}
    break;

    default:
		{

    }
		break;
	}

  DCDC_ctrl = ((V12board		& 0x01) << 7) +
              ((V12motor		& 0x01)	<< 5) +
              ((HSM           & 0x01)	<< 3) +
              (((PB1_restart || PB2_restart) & 0x01)	<< 0);

  if(DCrestart){
    PB1_restart=0;
    PB2_restart=0;
  }
}
#endif

// -----------------------------------------------------------------------------------------------------------------------------
// Finite state machine - DCDC power management - Target BAT_R1
// -----------------------------------------------------------------------------------------------------------------------------
#ifdef BAT_R1
void dcdc_management(void){

	// ----- EVENTS -------------------------------------------------- //
  if(V12board_F==0 && V12motor_F==0 && HSM_F==0){
		if(PB1_debounce){
			PB1_debounce=0;
			if(V12board || V12motor)            {state_fsm = OFF_BOARD_MOTORS;}     // if V12board or V12motor is on, switch off
			else                                {state_fsm = ON_BOARD;}             // else if V12board or V12motor is off, switch on
		}

		if(PB2_debounce){
			PB2_debounce=0;
			if      (HSM)                         	{state_fsm = ON_BOARD;}             // if HSM is on, switch off
			else if (!HSM && V12board && V12motor)	{state_fsm = ON_BOARD_MOTORS;}      // else if V12motor is off and V12board is on, switch on
		}
	}

	else{
		if(V12board_F==0 && V12motor_F==0 && HSM_F==1){
			if(PB1_debounce){
				PB1_debounce=0;
				if(V12board && V12motor)          {state_fsm = OFF_BOARD_MOTORS;}     // if V12board and V12motor are on, switch off
				else                              {state_fsm = ON_BOARD;}             // else if V12board and V12motor are off, switch on
			}
			else{
				if(PB2_restart==0)                {state_fsm = FAULT_MOTORS;}
				else{
					if(V12board && V12motor)				{state_fsm = ON_BOARD_MOTORS;}      // if V12board and V12motor are on, switch off
					else                            {state_fsm = OFF_BOARD_MOTORS;}     // else if V12board and V12motor are off, switch on

          HSM_F=0;
          PB2_restart=0;
				}
			}
		}
		else if(V12board_F==1 || V12motor_F==1){
			if(PB1_restart==0){
				if(HSM_F==1)     {state_fsm = FAULT_BOARD_MOTORS;}
				else             {state_fsm = FAULT_BOARD;}
			}
			else if(PB1_restart==1){
				state_fsm = ON_BOARD;
				V12board_F=0;
				V12motor_F=0;
        PB1_restart=0;
        PB2_debounce=0;
			}
		}
	}

  // ----- FINITE STATE MACHINE ------------------------------------ //

	switch(state_fsm){

		case START:
		{
      timerFSM++;
			state_fsm_prev = START;

			if(timerFSM >= 10){
				state_fsm = READY;
			}
    }
		break;

		case READY:
		{
      timerFSM = 0;
			PB1_LED_RED;
			PB2_LED_RED;
		}
    break;

		case OFF_BOARD_MOTORS:
		{
      EN_V12board_OFF;        // switch off V12board
      EN_V12motor_OFF;        // switch off V12motor
      HSM_EN_OFF;             // switch off HSM

      V12board=0;             // switch off V12board
			V12motor=0;             // switch off V12motor
			HSM=0;                  // switch off HSM
			PB1_LED_RED;
			PB2_LED_RED;
    }
    break;

		case ON_BOARD:
    {
			EN_V12board_ON;                             // switch on V12board
      //EN_V12motor_OFF;                            // switch off V12motor  - for iCub!
      if(V12motor==0){
        if(timer_delay_dcdc < timer_delay_dcdc_max){
          timer_delay_dcdc++;
        }
        else{
          EN_V12motor_ON;                            // switch on V12motor     - for CER!
          V12motor=1;             // switch on V12motor       - for CER!
          timer_delay_dcdc=0;
        }
      }

      HSM_EN_OFF;                                 // switch off HSM
      V12board=1;             // switch on V12board

      // V12motor=0;             // switch off V12motor   - for iCub!
			HSM=0;                  // switch off HSM
      //if(V12board==0){                                  // - for iCub
      if(V12board==0 || V12motor==0){                     // - for CER
        if(toggle_100ms)  {PB1_LED_GREEN;}
        else              {PB1_LED_OFF;}
			}
      else                {PB1_LED_GREEN;}
			PB2_LED_RED;
		}
    break;

		case ON_BOARD_MOTORS:
    {
      EN_V12board_ON;                             // switch on V12board
      EN_V12motor_ON;                             // switch on V12motor
      HSM_EN_ON;                                  // switch on HSM

      V12board=1;             // switch on V12board
			V12motor=1;             // switch on V12motor
			HSM=1;                  // switch on HSM
      //if(V12board==0){                          // - for iCub
      if(V12board==0 || V12motor==0){             // - for CER
        if(toggle_100ms)  {PB1_LED_GREEN;}
        else              {PB1_LED_OFF;}
			}
      else                {PB1_LED_GREEN;}

      //if(V12motor==0 || HSM_PG==0){             // - for iCub
      if(HSM_PG==0){                              // - for CER
        if(toggle_100ms)  {PB2_LED_GREEN;}
        else              {PB2_LED_OFF;}
			}
      else                {PB2_LED_GREEN;}
		}
    break;

		case FAULT_BOARD:
		{
      EN_V12board_OFF;                            // switch off V12board
      EN_V12motor_OFF;                            // switch off V12motor
      HSM_EN_OFF;                                 // switch off HSM

      V12board=0;             // switch off V12board
			V12motor=0;             // switch off V12motor
			HSM=0;                  // switch off HSM
			if(toggle_100ms)  {PB1_LED_RED;}
			else              {PB1_LED_OFF;}
			PB2_LED_RED;
		}
    break;

		case FAULT_MOTORS:
		{
      //EN_V12board_ON;                             // switch on V12board
      //EN_V12motor_OFF;                            // switch off V12motor
      HSM_EN_OFF;                                 // switch off HSM

      //V12board=1;           // switch on V12board
			//V12motor=0;           // switch off V12motor
			HSM=0;                  // switch off HSM
      PB1_LED_GREEN;
			if(toggle_100ms)  {PB2_LED_RED;}
			else              {PB2_LED_OFF;}
		}
    break;

		case FAULT_BOARD_MOTORS:
		{
      EN_V12board_OFF;        // switch off V12board
      EN_V12motor_OFF;        // switch off V12motor
      HSM_EN_OFF;             // switch off HSM

      V12board=0;             // switch off V12board
			V12motor=0;             // switch off V12motor
			HSM=0;                  // switch off HSM
			if(toggle_100ms)  {PB1_LED_RED;       PB2_LED_RED;}
			else              {PB1_LED_OFF;       PB2_LED_OFF;}
		}
    break;

    default:
		{

    }
		break;

	}

  DCDC_ctrl = ((V12board		& 0x01) << 7) +
              ((V12motor		& 0x01)	<< 5) +
              ((HSM           & 0x01)	<< 3) +
              (((PB1_restart || PB2_restart) & 0x01)	<< 0);

  if(DCrestart){
    PB1_restart=0;
    PB2_restart=0;
  }
}
#endif

// -----------------------------------------------------------------------------------------------------------------------------
// Timers
// -----------------------------------------------------------------------------------------------------------------------------
void HAL_TIM_PeriodElapsedCallback(TIM_HandleTypeDef *htim){
  if(htim->Instance==TIM1){        // timer 10ms
    if(HAL_GPIO_ReadPin(CPU)==0 || HAL_GPIO_ReadPin(GPIO1)==0){
      if(PB1_counter_debounce<timer_debounce){
				PB1_counter_debounce++;
			}
      else if(PB1_counter_debounce==timer_debounce){
        PB1_debounce=1;
        PB1_counter_debounce++;
      }
      else if(PB1_counter_debounce<timer_restart && (V12board_F==1)){
        PB1_counter_debounce++;
      }
      else if(V12board_F==1){
        PB1_status=1;
        HAL_TIM_Base_Stop_IT(&htim1);
				PB1_restart=1;                          // comando valido per il restart dopo il fault
				PB1_debounce=0;
      }
    }
    else{
      PB1_status=1;
      HAL_TIM_Base_Stop_IT(&htim1);
    }
  }
  if(htim->Instance==TIM2){        // timer 10ms
    if(HAL_GPIO_ReadPin(MOTORS)==0 || HAL_GPIO_ReadPin(GPIO2)==0){
      if(PB2_counter_debounce<timer_debounce){
				PB2_counter_debounce++;
			}
      else if(PB2_counter_debounce==timer_debounce){
        PB2_debounce=1;
        PB2_counter_debounce++;
      }
      else if(PB2_counter_debounce<timer_restart && (V12motor_F==1 || HSM_F==1)){
        PB2_counter_debounce++;
      }
      else if(V12motor_F==1 || HSM_F==1){
        PB2_status=1;
        HAL_TIM_Base_Stop_IT(&htim2);
				PB2_restart=1;                          // comando valido per il restart dopo il fault
				PB2_debounce=0;
      }
    }
    else{
      PB2_status=1;
      HAL_TIM_Base_Stop_IT(&htim2);
    }
  }
  if(htim->Instance==TIM6){         // timer 100us
  }
  if(htim->Instance==TIM7){         // timer 1ms
    CANBUS();
    dcdc_management();
    //HAL_TIM_Base_Stop_IT(&htim10);
    //timeout=1;
  }
  if(htim->Instance==TIM10){        // timer 10ms
    displayCharge();
    checkHSM();
    #ifdef BAT_iCub3
      FAULT_CHECK();
    #endif
  }
  if(htim->Instance==TIM11){        // timer 100ms
    toggle_100ms = toggle_100ms^1;
  }
  if(htim->Instance==TIM13){        // timer 1s
    toggle_1s = toggle_1s^1;
    Display_uOLED_128_G2();
  }
}

// -----------------------------------------------------------------------------------------------------------------------------
// Push buttons
// -----------------------------------------------------------------------------------------------------------------------------
void HAL_GPIO_EXTI_Callback(uint16_t GPIO_Pin){
  if(GPIO_Pin==GPIO_PIN_7 || GPIO_Pin==GPIO_PIN_0){               // PB1 or external button GPIO1
    if(PB1_status==1){
      PB1_status=0;
      PB1_counter_debounce=0;
      HAL_TIM_Base_Start_IT(&htim1);   // 10ms
    }

  }
  if(GPIO_Pin==GPIO_PIN_10 || GPIO_Pin==GPIO_PIN_1){        // PB2 or external button GPIO2
    if(PB2_status==1){
      PB2_status=0;
      PB2_counter_debounce=0;
      HAL_TIM_Base_Start_IT(&htim2);   // 10ms
    }
  }
  if(GPIO_Pin==GPIO_PIN_13){        // HSM_nFLT
    if(HAL_GPIO_ReadPin(HSM_nFLT) == 0)   {V48motor_FLT_ON;     HSM_F=1;}
    else                                  {V48motor_FLT_OFF;    HSM_F=0;}
  }
  if(GPIO_Pin==GPIO_PIN_14){        // HSM_nPG
    if(HAL_GPIO_ReadPin(HSM_nPG) == 0)    {V48motor_PG_ON;      HSM_PG=1;}
    else                                  {V48motor_PG_OFF;     HSM_PG=0;}
  }

  if(GPIO_Pin==GPIO_PIN_6 || GPIO_Pin==GPIO_PIN_8 || GPIO_Pin==GPIO_PIN_9){        // FAULT_ICUB, FAULT_GPIO, JACK
    int_fault = 1;
  }

}

// -----------------------------------------------------------------------------------------------------------------------------
// USART
// -----------------------------------------------------------------------------------------------------------------------------
void HAL_UART_RxCpltCallback(UART_HandleTypeDef *huart){
  if(huart->Instance==USART2){
    UartReady = SET;      // Set transmission flag: trasfer complete
  }
}

void HAL_UART_TxCpltCallback(UART_HandleTypeDef *huart){
  if(huart->Instance==USART1){

  }
}

// -----------------------------------------------------------------------------------------------------------------------------
// ADC
// -----------------------------------------------------------------------------------------------------------------------------
void HAL_ADC_ConvCpltCallback(ADC_HandleTypeDef* hadc){
  //HAL_GPIO_TogglePin(LED_BT);
  //HAL_ADC_Stop_DMA(&hadc1);
  adc_measure.V_VINPUT    = (*(adc_values+0))*13.31;       	// mV
  adc_measure.V_EXTPS     = (*(adc_values+1))*13.31;       	// mV
  adc_measure.V_BATTERY   = (*(adc_values+2))*13.31;       	// mV
  adc_measure.V_V12board  = (*(adc_values+3))*3.75;       	// mV
  adc_measure.V_V12motor  = (*(adc_values+4))*3.75;         // mV
  adc_measure.I_V12board  = ((*(adc_values+5))-2060)*9;   // mA
  adc_measure.I_V12motor  = ((*(adc_values+6))-2040)*9;   // mA
  adc_measure.I_HSM       = ((*(adc_values+7))*8.5);       // mA

  //adc_measure.I_V12board  = (*(adc_values+5));
  //adc_measure.I_V12motor  = (*(adc_values+6));
  //adc_measure.I_HSM       = (*(adc_values+7));
  adc_measure.Temp_sensor = ((((*(adc_values+8))*3300)/4096)-760)/2.5+25;       	// Temperature (in °C) = {(VSENSE – V25) / Avg_Slope} + 25 (page 441)

  if(adc_measure.I_V12board > I_V12board_MAX){                    // Check for board overcurrent
    if(timer_fault_board < 10)  {timer_fault_board++;}
    else                        {V12board_F = 1;}
  }else{
    if(timer_fault_board > 0)   {timer_fault_board--;}
  }

  if(adc_measure.I_V12motor > I_V12motor_MAX){                    // Check for motors overcurrent
    if(timer_fault_motors < 10) {timer_fault_motors++;}
    else                        {V12motor_F = 1;}
  }else{
    if(timer_fault_motors > 0)  {timer_fault_motors--;}
  }

  if(adc_measure.I_HSM > I_HSM_MAX){                              // Check for HSM overcurrent
    if(timer_fault_HSM < 10)    {timer_fault_HSM++;}
    else                        {HSM_F = 1;}
  }else{
    if(timer_fault_HSM > 0)     {timer_fault_HSM--;}
  }

  calcMean();

}

void calcMean(){
  adc_samples.V_VINPUT[adc_sample]    = adc_measure.V_VINPUT;
  adc_samples.V_EXTPS[adc_sample]     = adc_measure.V_EXTPS;
  adc_samples.V_BATTERY[adc_sample]   = adc_measure.V_BATTERY;
  adc_samples.V_V12board[adc_sample]  = adc_measure.V_V12board;
  adc_samples.V_V12motor[adc_sample]  = adc_measure.V_V12motor;
  adc_samples.I_V12board[adc_sample]  = adc_measure.I_V12board;
  adc_samples.I_V12motor[adc_sample]  = adc_measure.I_V12motor;
  adc_samples.I_HSM[adc_sample]       = adc_measure.I_HSM;

  if(adc_sample < (nr_adc_sample-1))  {adc_sample++;}
  else                                {adc_sample=0;}

  mean.V_VINPUT=0;
  mean.V_EXTPS=0;
  mean.V_BATTERY=0;
  mean.V_V12board=0;
  mean.V_V12motor=0;
  mean.I_V12board=0;
  mean.I_V12motor=0;
  mean.I_HSM =0;

  for(uint16_t i=0; i < nr_adc_sample; i++){
    mean.V_VINPUT   += adc_samples.V_VINPUT[i];
    mean.V_EXTPS    += adc_samples.V_EXTPS[i];
    mean.V_BATTERY  += adc_samples.V_BATTERY[i];
    mean.V_V12board += adc_samples.V_V12board[i];
    mean.V_V12motor += adc_samples.V_V12motor[i];
    mean.I_V12board += adc_samples.I_V12board[i];
    mean.I_V12motor += adc_samples.I_V12motor[i];
    mean.I_HSM      += adc_samples.I_HSM[i];
  }

  mean.V_VINPUT   = mean.V_VINPUT   / nr_adc_sample;
  mean.V_EXTPS    = mean.V_EXTPS    / nr_adc_sample;
  mean.V_BATTERY  = mean.V_BATTERY  / nr_adc_sample;
  mean.V_V12board = mean.V_V12board / nr_adc_sample;
  mean.V_V12motor = mean.V_V12motor / nr_adc_sample;
  mean.I_V12board = mean.I_V12board / nr_adc_sample;
  mean.I_V12motor = mean.I_V12motor / nr_adc_sample;
  mean.I_HSM      = mean.I_HSM      / nr_adc_sample;
}

// -----------------------------------------------------------------------------------------------------------------------------
// Display_uOLED_128_G2
// -----------------------------------------------------------------------------------------------------------------------------
void Display_uOLED_128_G2(){
//  uOLED_Voltages[0]=0x0001;
//  uOLED_Voltages[1]=mean.V_VINPUT;
//  uOLED_Voltages[2]=mean.V_EXTPS;
//  uOLED_Voltages[3]=mean.V_BATTERY;
//  uOLED_Voltages[4]=mean.V_V12board;
//  uOLED_Voltages[5]=mean.V_V12motor;

  //((bat_voltage-b)/a);

  if(mean.V_BATTERY > Battery_high)       {Battery_charge=100;}
  else if(mean.V_BATTERY < Battery_low)   {Battery_charge=0;}
  else                                    {Battery_charge = 100*(mean.V_BATTERY-Battery_low)/(Battery_high-Battery_low);}

  //uOLED_Parameters[0]
  //uOLED_Parameters[1]
  uOLED_Parameters[2] = (state_fsm<<8) + (state_fsm_boards<<4) + (state_fsm_motors);
  uOLED_Parameters[3]  = Battery_charge;
  uOLED_Parameters[4]  = mean.V_VINPUT;
  uOLED_Parameters[5]  = mean.V_EXTPS;
  uOLED_Parameters[6]  = mean.V_BATTERY;
  uOLED_Parameters[7]  = mean.V_V12board;
  uOLED_Parameters[8]  = mean.V_V12motor;
  uOLED_Parameters[9]  = mean.I_V12board;
  uOLED_Parameters[10] = mean.I_V12motor;
  uOLED_Parameters[11] = mean.I_HSM;

  uOLED_Parameters[12] = (100*HSM_PG) + (10*V12motor) + (V12board);
  uOLED_Parameters[13] = (100*HSM_F) + (10*V12motor_F) + (V12board_F);

  HAL_UART_Transmit_DMA(&huart1, (uint8_t*)uOLED_Parameters, sizeof(uOLED_Parameters));
  //HAL_UART_Transmit_IT(&huart1, (uint8_t*)voltages, 12);
}

// -----------------------------------------------------------------------------------------------------------------------------
// Bluetooth configuration
// -----------------------------------------------------------------------------------------------------------------------------
void Bluetooth(){
  HAL_UART_Receive_DMA(&huart2, (uint8_t*)aRxBuffer, 5);
	HAL_GPIO_WritePin(BT_SW_WAKE, GPIO_PIN_SET);
	WaitUartResponse("CMD");		// CMD

	HAL_UART_Receive_DMA(&huart2, (uint8_t*)aRxBuffer, 5);
	HAL_UART_Transmit_DMA(&huart2, (uint8_t*)RN4020_Reset, sizeof(RN4020_Reset)-1);
	WaitUartResponse("AOK");		// AOK

  HAL_UART_Receive_DMA(&huart2, (uint8_t*)aRxBuffer, 8);
	HAL_UART_Transmit_DMA(&huart2, (uint8_t*)RN4020_Reboot, sizeof(RN4020_Reboot)-1);
	WaitUartResponse("Reboot");		// REBOOT

	HAL_UART_Receive_DMA(&huart2, (uint8_t*)aRxBuffer, 5);
	WaitUartResponse("CMD");		// CMD

	HAL_UART_Receive_DMA(&huart2, (uint8_t*)aRxBuffer, 5);
	HAL_UART_Transmit_DMA(&huart2, (uint8_t*)RN4020_Setting_A, sizeof(RN4020_Setting_A)-1);
	WaitUartResponse("AOK");		// AOK

	HAL_UART_Receive_DMA(&huart2, (uint8_t*)aRxBuffer, 5);
	HAL_UART_Transmit_DMA(&huart2, (uint8_t*)RN4020_Setting_B, sizeof(RN4020_Setting_B)-1);
	WaitUartResponse("AOK");		// AOK

	HAL_UART_Receive_DMA(&huart2, (uint8_t*)aRxBuffer, 5);
	HAL_UART_Transmit_DMA(&huart2, (uint8_t*)RN4020_Setting_C, sizeof(RN4020_Setting_C)-1);
	WaitUartResponse("AOK");		// AOK

	HAL_UART_Receive_DMA(&huart2, (uint8_t*)aRxBuffer, 8);
	HAL_UART_Transmit_DMA(&huart2, (uint8_t*)RN4020_Reboot, sizeof(RN4020_Reboot)-1);
	WaitUartResponse("Reboot");		// REBOOT

	HAL_UART_Receive_DMA(&huart2, (uint8_t*)aRxBuffer, 5);
	WaitUartResponse("CMD");		// CMD

	HAL_UART_Receive_DMA(&huart2, (uint8_t*)aRxBuffer, 5);
	HAL_UART_Transmit_DMA(&huart2, (uint8_t*)RN4020_Advertise, sizeof(RN4020_Advertise)-1);
	WaitUartResponse("AOK");		// AOK

  HAL_GPIO_WritePin(BT_SW_WAKE, GPIO_PIN_RESET);
}

// -----------------------------------------------------------------------------------------------------------------------------
// Bluetooth response
// -----------------------------------------------------------------------------------------------------------------------------
void WaitUartResponse(uint8_t* response)
{
	int i;
  timeout=0;
  //HAL_TIM_Base_Start_IT(&htim10);
  //HAL_TIM_IRQHandler(&htim10);

	while (UartReady != SET){     // && timeout != 1
		}
	UartReady = RESET;

	if(Buffercmp((uint8_t*)aRxBuffer, (uint8_t*)response, sizeof(response)) == 0){
		UartReady = SET;
	}

	while (UartReady != SET){     // && timeout != 1
      //HAL_GPIO_TogglePin(LED_BT);
		}
	UartReady = RESET;

	for(i=0; i<sizeof(aRxBuffer); i++)		{aRxBuffer[i]=0;}
}

// -----------------------------------------------------------------------------------------------------------------------------
// CAN configuration
// -----------------------------------------------------------------------------------------------------------------------------
static void CAN_Config(void)
{
  static CanTxMsgTypeDef        TxMessage;
  static CanRxMsgTypeDef        RxMessage;

  hcan1.pTxMsg = &TxMessage;
  hcan1.pRxMsg = &RxMessage;

  if (HAL_CAN_Init(&hcan1) != HAL_OK)
  {
    /* Initialization Error */
    Error_Handler();
  }

  /*##-3- Configure Transmission process #####################################*/
  hcan1.pTxMsg->StdId = 0x621;
  hcan1.pTxMsg->ExtId = 0x01;
  hcan1.pTxMsg->RTR = CAN_RTR_DATA;
  //hcan1.pTxMsg->IDE = CAN_ID_EXT;
  hcan1.pTxMsg->IDE = CAN_ID_STD;
  hcan1.pTxMsg->DLC = 8;
}

// -----------------------------------------------------------------------------------------------------------------------------
// CAN messages management
// -----------------------------------------------------------------------------------------------------------------------------
void CANBUS(void){
	switch(can_message){
    case 0x00:
    {
      hcan1.pTxMsg->StdId   = 0x621;              // Polling
      hcan1.pTxMsg->Data[0] = 0xFF;               // Firmware version message
      hcan1.pTxMsg->Data[1] = 0x02;               // Board type
      hcan1.pTxMsg->Data[2] = Firmware_vers;      // Firmware version
      hcan1.pTxMsg->Data[3] = Revision_vers;      // Revision version
      hcan1.pTxMsg->Data[4] = Build_number;       // Build number
      hcan1.pTxMsg->Data[5] = 0;
      hcan1.pTxMsg->Data[6] = 0;
      hcan1.pTxMsg->Data[7] = 0;
      HAL_CAN_Transmit_IT(&hcan1);
      can_message = 1;
    }
    break;

    case 0x01:
    {
      hcan1.pTxMsg->StdId   = 0x621;
      hcan1.pTxMsg->Data[0] = 0x80;
      hcan1.pTxMsg->Data[1] = 0x00;
      hcan1.pTxMsg->Data[2] = 0x00;
      hcan1.pTxMsg->Data[3] = (adc_measure.Temp_sensor >> 8) & 0xFF;
      hcan1.pTxMsg->Data[4] = adc_measure.Temp_sensor & 0xFF;
      hcan1.pTxMsg->Data[5] = 0;
      hcan1.pTxMsg->Data[6] = 0;
      hcan1.pTxMsg->Data[7] = 0;
      HAL_CAN_Transmit_IT(&hcan1);
      can_message = 2;
    }
    break;

    case 0x02:
    {
      hcan1.pTxMsg->StdId   = 0x621;
      hcan1.pTxMsg->Data[0] = 0x81;               // Voltage message
      hcan1.pTxMsg->Data[1] = 0x00;
      hcan1.pTxMsg->Data[2] = (mean.V_VINPUT >> 8) & 0xFF;
      hcan1.pTxMsg->Data[3] = mean.V_VINPUT & 0xFF;
      hcan1.pTxMsg->Data[4] = (mean.V_EXTPS >> 8) & 0xFF;
      hcan1.pTxMsg->Data[5] = mean.V_EXTPS & 0xFF;
      hcan1.pTxMsg->Data[6] = (mean.V_BATTERY >> 8) & 0xFF;
      hcan1.pTxMsg->Data[7] = mean.V_BATTERY & 0xFF;
      HAL_CAN_Transmit_IT(&hcan1);
      can_message = 3;
    }
    break;

    case 0x03:
    {
      hcan1.pTxMsg->StdId   = 0x621;
      hcan1.pTxMsg->Data[0] = 0x82;               // Voltage message
      hcan1.pTxMsg->Data[1] = 0x00;
      hcan1.pTxMsg->Data[2] = (mean.V_V12board >> 8) & 0xFF;
      hcan1.pTxMsg->Data[3] = mean.V_V12board & 0xFF;
      hcan1.pTxMsg->Data[4] = (mean.V_V12motor >> 8) & 0xFF;
      hcan1.pTxMsg->Data[5] = mean.V_V12motor & 0xFF;
      hcan1.pTxMsg->Data[6] = 0x00;
      hcan1.pTxMsg->Data[7] = 0x00;
      HAL_CAN_Transmit_IT(&hcan1);
      can_message = 4;
    }
    break;

    case 0x04:
    {
      hcan1.pTxMsg->StdId   = 0x621;
      hcan1.pTxMsg->Data[0] = 0x83;               // Current message
      hcan1.pTxMsg->Data[1] = 0x00;
      hcan1.pTxMsg->Data[2] = (mean.I_V12board >> 8) & 0xFF;
      hcan1.pTxMsg->Data[3] = mean.I_V12board & 0xFF;
      hcan1.pTxMsg->Data[4] = (mean.I_V12motor >> 8) & 0xFF;
      hcan1.pTxMsg->Data[5] = mean.I_V12motor & 0xFF;
      hcan1.pTxMsg->Data[6] = (mean.I_HSM >> 8) & 0xFF;
      hcan1.pTxMsg->Data[7] = mean.I_HSM & 0xFF;
      HAL_CAN_Transmit_IT(&hcan1);
      can_message = 0;
    }
    break;

    default:
    {
    }
    break;
  }
}

// -----------------------------------------------------------------------------------------------------------------------------
// -----------------------------------------------------------------------------------------------------------------------------
/**
  * @brief  Transmission  complete callback in non blocking mode
  * @param  hcan: pointer to a CAN_HandleTypeDef structure that contains
  *         the configuration information for the specified CAN.
  * @retval None
  */
void HAL_CAN_TxCpltCallback(CAN_HandleTypeDef* hcan)
{
  HAL_GPIO_WritePin(CAN1_LED, toggle_100ms);
}

// -----------------------------------------------------------------------------------------------------------------------------
// -----------------------------------------------------------------------------------------------------------------------------
/**
  * @brief  Compares two buffers.
  * @param  pBuffer1, pBuffer2: buffers to be compared.
  * @param  BufferLength: buffer's length
  * @retval 0  : pBuffer1 identical to pBuffer2
  *         >0 : pBuffer1 differs from pBuffer2
  */
static uint16_t Buffercmp(uint8_t* pBuffer1, uint8_t* pBuffer2, uint16_t BufferLength)
{
  while (BufferLength--)
  {
    if ((*pBuffer1) != *pBuffer2)
    {
      return BufferLength;
    }
    pBuffer1++;
    pBuffer2++;
  }

  return 0;
}

// -----------------------------------------------------------------------------------------------------------------------------
// Light up leds to display battery voltage
// -----------------------------------------------------------------------------------------------------------------------------
void displayCharge(void){
    //int adc_buffer_last=adc_buffer;

    if(mean.V_VINPUT < (VTH[0]+vhyst)){
        if((VTH[0]-mean.V_VINPUT) > vtol)   {vhyst=0;}
        else                                {vhyst=vtol;}
        lightupLed(0x81);     // light up LED0
    }
    else if(mean.V_VINPUT < (VTH[1]+vhyst)){
        if((VTH[1]-mean.V_VINPUT) > vtol)   {vhyst=0;}
        else                                {vhyst=vtol;}
        lightupLed(0x81);     // light up LED0
    }
    else if(mean.V_VINPUT < (VTH[2]+vhyst)){
        if((VTH[2]-mean.V_VINPUT) > vtol)   {vhyst=0;}
        else                                {vhyst=vtol;}
        lightupLed(0x01);     // light up LED0
    }
    else if(mean.V_VINPUT < (VTH[3]+vhyst)){
        if((VTH[3]-mean.V_VINPUT) > vtol)   {vhyst=0;}
        else                                {vhyst=vtol;}
        lightupLed(0x03);     // light up LED1
    }
    else if(mean.V_VINPUT < (VTH[4]+vhyst)){
        if((VTH[4]-mean.V_VINPUT) > vtol)   {vhyst=0;}
        else                                {vhyst=vtol;}
        lightupLed(0x07);     // light up LED2
    }
    else if(mean.V_VINPUT < (VTH[5]+vhyst)){
        if((VTH[5]-mean.V_VINPUT) > vtol)   {vhyst=0;}
        else                                {vhyst=vtol;}
        lightupLed(0x0f);     // light up LED3
    }
    else if(mean.V_VINPUT < (VTH[6]+vhyst)){
        if((VTH[6]-mean.V_VINPUT) > vtol)   {vhyst=0;}
        else                                {vhyst=vtol;}
        lightupLed(0x1f);     // light up LED4
    }
    else{
        vhyst=0;
        lightupLed(0x9f);     // light up LED4
    }
}

// -----------------------------------------------------------------------------------------------------------------------------
// Turn on/off and blink V-meter leds
// -----------------------------------------------------------------------------------------------------------------------------
void lightupLed(uint16_t lightup){
  uint16_t blink = toggle_100ms & (lightup>>7 & 0x01);
  HAL_GPIO_WritePin(LED0_BATTERY, ((!(lightup    & 0x01)) || blink));
  HAL_GPIO_WritePin(LED1_BATTERY, ((!(lightup>>1 & 0x01)) || blink));
  HAL_GPIO_WritePin(LED2_BATTERY, ((!(lightup>>2 & 0x01)) || blink));
  HAL_GPIO_WritePin(LED3_BATTERY, ((!(lightup>>3 & 0x01)) || blink));
  HAL_GPIO_WritePin(LED4_BATTERY, ((!(lightup>>4 & 0x01)) || blink));
}

// -----------------------------------------------------------------------------------------------------------------------------
// Check for HSM mosfet broken
// -----------------------------------------------------------------------------------------------------------------------------
void checkHSM(){
  if(HAL_GPIO_ReadPin(HSM_nFLT) == 0)   {V48motor_FLT_ON;}
  else                                  {V48motor_FLT_OFF;}
  if(HAL_GPIO_ReadPin(HSM_nPG) == 0)    {V48motor_PG_ON;}
  else                                  {V48motor_PG_OFF;}
}

// ----------------------------------------------------------------------------
// FAULT check
// ----------------------------------------------------------------------------
void FAULT_CHECK(void){
  if(int_fault){

    if(HAL_GPIO_ReadPin(JACK) == 1)   {FAULT_REM_ON;}     // check for the link of the fault push button
    else                              {FAULT_REM_OFF;}

    if( HAL_GPIO_ReadPin(FAULT_REM) == 1 && (
      ( HAL_GPIO_ReadPin(JACK) == 0 && HAL_GPIO_ReadPin(FAULT_GPIO) == 1) ||        // there isn't the jack
      ( HAL_GPIO_ReadPin(JACK) == 1 && HAL_GPIO_ReadPin(FAULT_GPIO) == 0) ))        // there is the jack
      {                     // NO FAULT
          if(filter_fault_gpio<timer_debounce){
            filter_fault_gpio++;
          }
          else if(filter_fault_gpio==timer_debounce){     // valid command
            LED_BT_OFF;
            fault_button=0;
            filter_fault_gpio=0;
            int_fault=0;
          }
       }
       else{                // FAULT!!!!
          if(filter_fault_gpio<timer_debounce){
              filter_fault_gpio++;
          }
          else if(filter_fault_gpio==timer_debounce){     // valid command
            LED_BT_ON;
            fault_button=1;
            filter_fault_gpio=0;
            int_fault=0;
          }
      }
    }
}

// -----------------------------------------------------------------------------------------------------------------------------
// -----------------------------------------------------------------------------------------------------------------------------
/**
  * @brief  This function is executed in case of error occurrence.
  * @param  None
  * @retval None
  */
static void Error_Handler(void){
}

/* USER CODE END 4 */

/************************ (C) COPYRIGHT STMicroelectronics *****END OF FILE****/
